AUTOSAR XML (schema 4-2-2)
package /Components
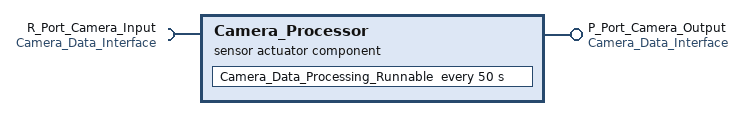
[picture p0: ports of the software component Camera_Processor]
  sensor actuator sw component type Camera_Processor
    provide port P_Port_Camera_Output: provided-interface=Camera_Data_Interface
    require port R_Port_Camera_Input: required-interface=Camera_Data_Interface
    behavior Camera_Proc_Internal_Behavior
      data send completed event Camera_Data_Sent: start-on-event=Camera_Data_Processing_Runnable, event-source=R_Port_Camera_Input
      timing event Camera_Periodic_Timer: start-on-event=Camera_Data_Processing_Runnable, period=50
      runnable Camera_Data_Processing_Runnable: symbol=CameraImg
        data-receive-point-by-arguments:
          access Camera_Image_Input: accessed-variable=R_Port_Camera_Input.Camera_Image
        data-send-points:
          access Camera_Image_Output: accessed-variable=P_Port_Camera_Output.Camera_Image
